# ATSAMV70Q19 device description
Architecture: CORTEX-M7; Family: SAMV; Series: SAMV70
Registers are 32-bit, read-write, no defined reset value unless marked. A register's access mark holds for its fields unless they carry their own. Offsets are from the block's base; [hi:lo] are bit positions; {n}, {i} and the like mark numbered series.

## SPI — Serial Peripheral Interface
Instances: SPI0 0x40008000, SPI1 0x40058000
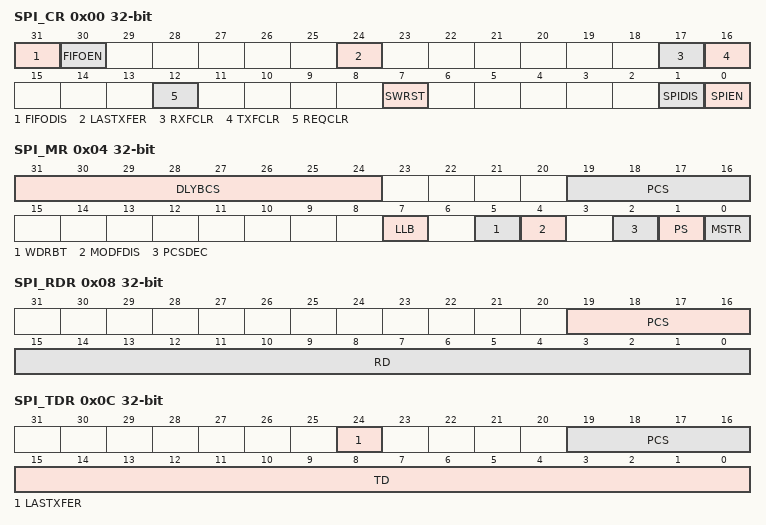
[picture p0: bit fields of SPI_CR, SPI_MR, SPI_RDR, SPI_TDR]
0x00 SPI_CR wo — Control Register
  [31] FIFODIS — FIFO Disable
  [30] FIFOEN — FIFO Enable
  [24] LASTXFER — Last Transfer
  [17] RXFCLR — Receive FIFO Clear
  [16] TXFCLR — Transmit FIFO Clear
  [12] REQCLR — Request to Clear the Comparison Trigger
  [7] SWRST — SPI Software Reset
  [1] SPIDIS — SPI Disable
  [0] SPIEN — SPI Enable
0x04 SPI_MR — Mode Register
  [31:24] DLYBCS — Delay Between Chip Selects
  [19:16] PCS — Peripheral Chip Select
  [7] LLB — Local Loopback Enable
  [5] WDRBT — Wait Data Read Before Transfer
  [4] MODFDIS — Mode Fault Detection
  [2] PCSDEC — Chip Select Decode
  [1] PS — Peripheral Select
  [0] MSTR — Master/Slave Mode
0x08 SPI_RDR ro — Receive Data Register
  [19:16] PCS — Peripheral Chip Select
  [15:0] RD — Receive Data
0x0C SPI_TDR wo — Transmit Data Register
  [24] LASTXFER — Last Transfer
  [19:16] PCS — Peripheral Chip Select
  [15:0] TD — Transmit Data
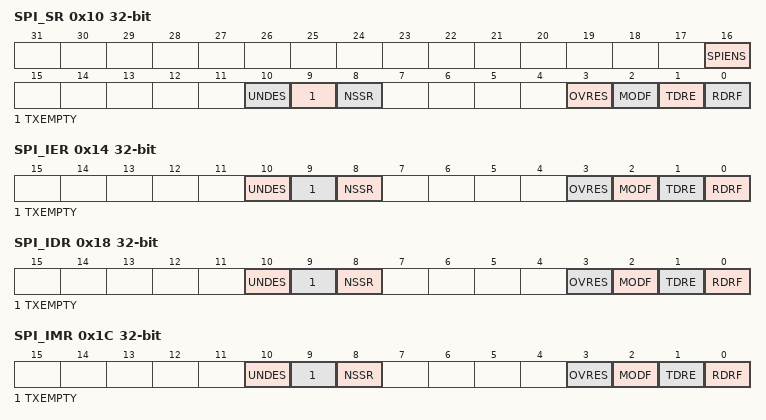
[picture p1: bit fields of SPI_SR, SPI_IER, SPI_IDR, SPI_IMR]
0x10 SPI_SR ro — Status Register
  [16] SPIENS — SPI Enable Status
  [10] UNDES — Underrun Error Status (Slave mode only) (cleared on read)
  [9] TXEMPTY — Transmission Registers Empty (cleared by writing SPI_TDR)
  [8] NSSR — NSS Rising (cleared on read)
  [3] OVRES — Overrun Error Status (cleared on read)
  [2] MODF — Mode Fault Error (cleared on read)
  [1] TDRE — Transmit Data Register Empty (cleared by writing SPI_TDR)
  [0] RDRF — Receive Data Register Full (cleared by reading SPI_RDR)
0x14 SPI_IER wo (atomic set of SPI_IMR) — Interrupt Enable Register
  [10] UNDES — Underrun Error Interrupt Enable
  [9] TXEMPTY — Transmission Registers Empty Enable
  [8] NSSR — NSS Rising Interrupt Enable
  [3] OVRES — Overrun Error Interrupt Enable
  [2] MODF — Mode Fault Error Interrupt Enable
  [1] TDRE — SPI Transmit Data Register Empty Interrupt Enable
  [0] RDRF — Receive Data Register Full Interrupt Enable
0x18 SPI_IDR wo (atomic clear of SPI_IMR) — Interrupt Disable Register
  [10] UNDES — Underrun Error Interrupt Disable
  [9] TXEMPTY — Transmission Registers Empty Disable
  [8] NSSR — NSS Rising Interrupt Disable
  [3] OVRES — Overrun Error Interrupt Disable
  [2] MODF — Mode Fault Error Interrupt Disable
  [1] TDRE — SPI Transmit Data Register Empty Interrupt Disable
  [0] RDRF — Receive Data Register Full Interrupt Disable
0x1C SPI_IMR ro (atomic read) — Interrupt Mask Register
  [10] UNDES — Underrun Error Interrupt Mask
  [9] TXEMPTY — Transmission Registers Empty Mask
  [8] NSSR — NSS Rising Interrupt Mask
  [3] OVRES — Overrun Error Interrupt Mask
  [2] MODF — Mode Fault Error Interrupt Mask
  [1] TDRE — SPI Transmit Data Register Empty Interrupt Mask
  [0] RDRF — Receive Data Register Full Interrupt Mask
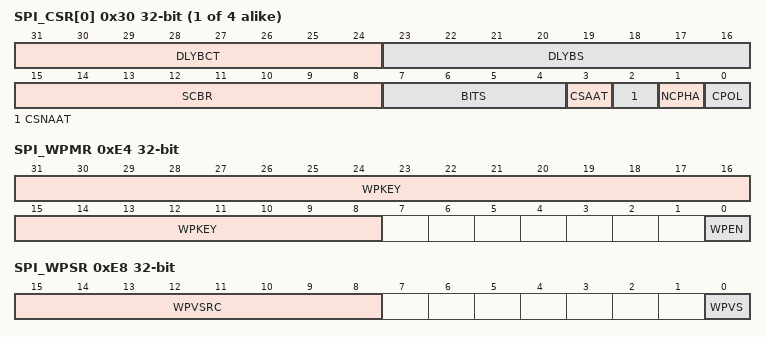
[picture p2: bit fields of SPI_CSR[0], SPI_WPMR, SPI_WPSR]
{0x30+4i} SPI_CSR[{i}] (i=0..3) — Chip Select Register (CS_number = 0) 0
  [31:24] DLYBCT — Delay Between Consecutive Transfers
  [23:16] DLYBS — Delay Before SPCK
  [15:8] SCBR — Serial Clock Bit Rate
  [7:4] BITS — Bits Per Transfer
    {v}=_{v+8}_BIT ({v+8} bits for transfer) (v=0..8)
  [3] CSAAT — Chip Select Active After Transfer
  [2] CSNAAT — Chip Select Not Active After Transfer (Ignored if CSAAT = 1)
  [1] NCPHA — Clock Phase
  [0] CPOL — Clock Polarity
0xE4 SPI_WPMR — Write Protection Mode Register
  [31:8] WPKEY — Write Protection Key
    0x535049=PASSWD (Writing any other value in this field aborts the write operation of the WPEN bit.Always reads as 0.)
  [0] WPEN — Write Protection Enable
0xE8 SPI_WPSR ro — Write Protection Status Register
  [15:8] WPVSRC — Write Protection Violation Source
  [0] WPVS — Write Protection Violation Status

## TRNG — True Random Number Generator
Instances: TRNG 0x40070000
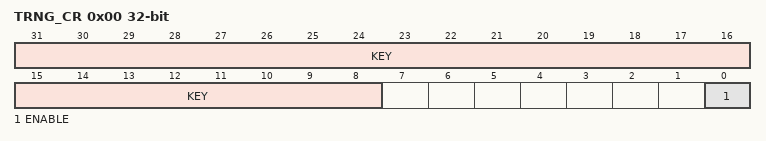
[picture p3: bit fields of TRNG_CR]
0x00 TRNG_CR wo — Control Register
  [31:8] KEY — Security Key
    0x524E47=PASSWD (Writing any other value in this field aborts the write operation.)
  [0] ENABLE — Enables the TRNG to Provide Random Values
0x10 TRNG_IER wo (atomic set of TRNG_IMR) — Interrupt Enable Register
  [0] DATRDY — Data Ready Interrupt Enable
0x14 TRNG_IDR wo (atomic clear of TRNG_IMR) — Interrupt Disable Register
  [0] DATRDY — Data Ready Interrupt Disable
0x18 TRNG_IMR ro (atomic read) — Interrupt Mask Register
  [0] DATRDY — Data Ready Interrupt Mask
0x1C TRNG_ISR ro (atomic clear) — Interrupt Status Register
  [0] DATRDY — Data Ready
0x50 TRNG_ODATA ro — Output Data Register
  [31:0] ODATA — Output Data

## Notices in the file
Copyright (c) 2017 Microchip Technology Inc.
SPDX-License-Identifier: Apache-2.0
Licensed under the Apache License, Version 2.0 (the "License");
you may not use this file except in compliance with the License.
You may obtain a copy of the License at
http://www.apache.org/licenses/LICENSE-2.0
Unless required by applicable law or agreed to in writing, software
distributed under the License is distributed on an "AS IS" BASIS,
WITHOUT WARRANTIES OR CONDITIONS OF ANY KIND, either express or implied.
See the License for the specific language governing permissions and
limitations under the License.
